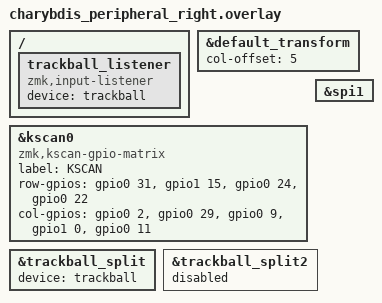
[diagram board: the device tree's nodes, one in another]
/*
 * Copyright (c) 2020 ZMK Contributors
 *
 * SPDX-License-Identifier: MIT
 */
 
#include "charybdis.dtsi"
#include "trackball.dtsi"
#include "split_input_common.dtsi"

&default_transform {
	col-offset = <5>;
};

&kscan0 {
    compatible = "zmk,kscan-gpio-matrix";
    label = "KSCAN";
	row-gpios
        = <&gpio0 31 GPIO_ACTIVE_HIGH>
        , <&gpio1 15 GPIO_ACTIVE_HIGH>
        , <&gpio0 24 GPIO_ACTIVE_HIGH>
	    , <&gpio0 22 GPIO_ACTIVE_HIGH>
        ;
	col-gpios
		= <&gpio0 2 (GPIO_ACTIVE_HIGH | GPIO_PULL_DOWN)>
		, <&gpio0 29 (GPIO_ACTIVE_HIGH | GPIO_PULL_DOWN)>
		, <&gpio0 9 (GPIO_ACTIVE_HIGH | GPIO_PULL_DOWN)>
		, <&gpio1 0  (GPIO_ACTIVE_HIGH | GPIO_PULL_DOWN)>
		, <&gpio0 11 (GPIO_ACTIVE_HIGH | GPIO_PULL_DOWN)>
		;
};

&spi1 {
    status = "okay";
};
&trackball_split { 
	device = <&trackball>; 
	};
&trackball_split2 { 
	status = "disabled"; 
};



/ {
    trackball_listener {
        compatible = "zmk,input-listener";
        device = <&trackball>;
    };
};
